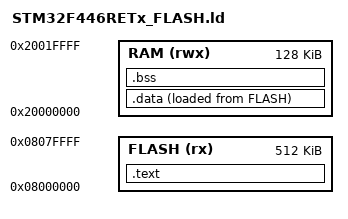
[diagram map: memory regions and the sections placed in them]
ENTRY(main)

MEMORY
{
    FLASH (rx)  : ORIGIN = 0x08000000, LENGTH = 512K
    RAM   (rwx) : ORIGIN = 0x20000000, LENGTH = 128K
}

SECTIONS
{
    .text :
    {
        . = ALIGN(4);
        *(.text*)
        *(.rodata*)
        . = ALIGN(4);
    } > FLASH

    .data :
    {
        . = ALIGN(4);
        *(.data*)
        . = ALIGN(4);
    } > RAM AT > FLASH

    .bss :
    {
        . = ALIGN(4);
        *(.bss*)
        *(COMMON)
        . = ALIGN(4);
    } > RAM
}
